AUTOSAR XML (schema 4-0-3)
package /ComponentTypes
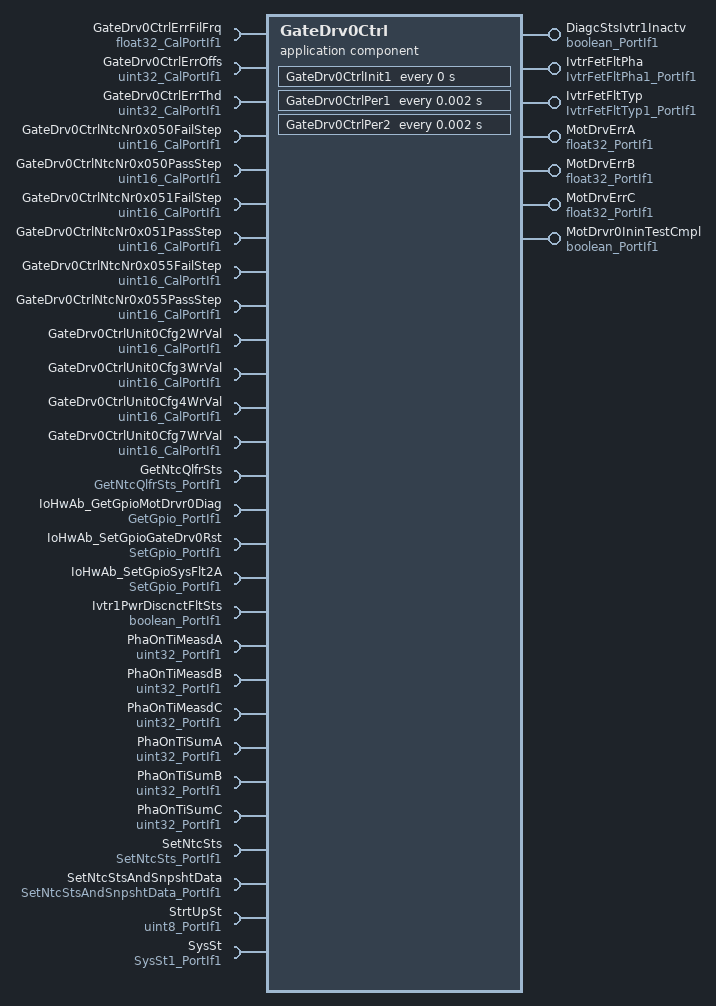
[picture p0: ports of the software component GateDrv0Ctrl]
  application sw component type GateDrv0Ctrl
    7 x provide port:
      DiagcStsIvtr1Inactv: nonqueued-sender-com-spec{data-element=Logl, init-value=0}, provided-interface=boolean_PortIf1
      IvtrFetFltPha: nonqueued-sender-com-spec{data-element=Val, init-value=0}, provided-interface=IvtrFetFltPha1_PortIf1
      IvtrFetFltTyp: nonqueued-sender-com-spec{data-element=Val, init-value=0}, provided-interface=IvtrFetFltTyp1_PortIf1
      MotDrvErrA: nonqueued-sender-com-spec{data-element=Val, init-value=0}, provided-interface=float32_PortIf1
      MotDrvErrB: nonqueued-sender-com-spec{data-element=Val, init-value=0}, provided-interface=float32_PortIf1
      MotDrvErrC: nonqueued-sender-com-spec{data-element=Val, init-value=0}, provided-interface=float32_PortIf1
      MotDrvr0IninTestCmpl: nonqueued-sender-com-spec{data-element=Logl, init-value=0}, provided-interface=boolean_PortIf1
    28 x require port:
      GateDrv0CtrlErrFilFrq: parameter-require-com-spec{init-value=1.8, parameter=Val}, required-interface=float32_CalPortIf1
      GateDrv0CtrlErrOffs: parameter-require-com-spec{init-value=0, parameter=Val}, required-interface=uint32_CalPortIf1
      GateDrv0CtrlErrThd: parameter-require-com-spec{init-value=180000, parameter=Val}, required-interface=uint32_CalPortIf1
      GateDrv0CtrlNtcNr0x050FailStep: parameter-require-com-spec{init-value=4096, parameter=Val}, required-interface=uint16_CalPortIf1
      GateDrv0CtrlNtcNr0x050PassStep: parameter-require-com-spec{init-value=2048, parameter=Val}, required-interface=uint16_CalPortIf1
      GateDrv0CtrlNtcNr0x051FailStep: parameter-require-com-spec{init-value=4096, parameter=Val}, required-interface=uint16_CalPortIf1
      GateDrv0CtrlNtcNr0x051PassStep: parameter-require-com-spec{init-value=2048, parameter=Val}, required-interface=uint16_CalPortIf1
      GateDrv0CtrlNtcNr0x055FailStep: parameter-require-com-spec{init-value=4096, parameter=Val}, required-interface=uint16_CalPortIf1
      GateDrv0CtrlNtcNr0x055PassStep: parameter-require-com-spec{init-value=2048, parameter=Val}, required-interface=uint16_CalPortIf1
      GateDrv0CtrlUnit0Cfg2WrVal: parameter-require-com-spec{init-value=2832, parameter=Val}, required-interface=uint16_CalPortIf1
      GateDrv0CtrlUnit0Cfg3WrVal: parameter-require-com-spec{init-value=3598, parameter=Val}, required-interface=uint16_CalPortIf1
      GateDrv0CtrlUnit0Cfg4WrVal: parameter-require-com-spec{init-value=4622, parameter=Val}, required-interface=uint16_CalPortIf1
      GateDrv0CtrlUnit0Cfg7WrVal: parameter-require-com-spec{init-value=7924, parameter=Val}, required-interface=uint16_CalPortIf1
      GetNtcQlfrSts: client-com-spec=Oper, required-interface=GetNtcQlfrSts_PortIf1
      IoHwAb_GetGpioMotDrvr0Diag: client-com-spec=Oper, required-interface=GetGpio_PortIf1
      IoHwAb_SetGpioGateDrv0Rst: client-com-spec=Oper, required-interface=SetGpio_PortIf1
      IoHwAb_SetGpioSysFlt2A: client-com-spec=Oper, required-interface=SetGpio_PortIf1
      Ivtr1PwrDiscnctFltSts: nonqueued-receiver-com-spec{data-element=Logl, filter=data-filter-type=ALWAYS, init-value=0}, required-interface=boolean_PortIf1
      PhaOnTiMeasdA: nonqueued-receiver-com-spec{data-element=Val, filter=data-filter-type=ALWAYS, init-value=0}, required-interface=uint32_PortIf1
      PhaOnTiMeasdB: nonqueued-receiver-com-spec{data-element=Val, filter=data-filter-type=ALWAYS, init-value=0}, required-interface=uint32_PortIf1
      PhaOnTiMeasdC: nonqueued-receiver-com-spec{data-element=Val, filter=data-filter-type=ALWAYS, init-value=0}, required-interface=uint32_PortIf1
      PhaOnTiSumA: nonqueued-receiver-com-spec{data-element=Val, filter=data-filter-type=ALWAYS, init-value=0}, required-interface=uint32_PortIf1
      PhaOnTiSumB: nonqueued-receiver-com-spec{data-element=Val, filter=data-filter-type=ALWAYS, init-value=0}, required-interface=uint32_PortIf1
      PhaOnTiSumC: nonqueued-receiver-com-spec{data-element=Val, filter=data-filter-type=ALWAYS, init-value=0}, required-interface=uint32_PortIf1
      SetNtcSts: client-com-spec=Oper, required-interface=SetNtcSts_PortIf1
      SetNtcStsAndSnpshtData: client-com-spec=Oper, required-interface=SetNtcStsAndSnpshtData_PortIf1
      StrtUpSt: nonqueued-receiver-com-spec{data-element=Val, filter=data-filter-type=ALWAYS, init-value=0}, required-interface=uint8_PortIf1
      SysSt: nonqueued-receiver-com-spec{data-element=Val, filter=data-filter-type=ALWAYS, init-value=3}, required-interface=SysSt1_PortIf1
    behavior GateDrv0Ctrl_InternalBehavior
      ar-typed-per-instance-memorys:
        36 x data, all with sw-calibration-access=READ-ONLY:
          dGateDrv0CtrlGateDrv0Diag{0..2}Val: type=uint16
          dGateDrv0CtrlGateDrv0OffsStVrfyPrmBitIdx: type=uint8
          dGateDrv0CtrlGateDrv0PhaOnTiSumAExp: type=uint32
          dGateDrv0CtrlGateDrv0PhaOnTiSumBExp: type=uint32
          dGateDrv0CtrlGateDrv0PhaOnTiSumCExp: type=uint32
          dGateDrv0CtrlGateDrv0StsVal: type=uint16
          dGateDrv0CtrlGateDrv0VrfyRes0Val: type=uint16
          dGateDrv0CtrlGateDrv0VrfyRes1Val: type=uint16
          GateDrv0CfgCnt: type=uint8
          GateDrv0CfgSecAtmpt: type=boolean
          GateDrv0Diag{0..2}Val: type=uint16
          GateDrv0OffStChkIdx: type=uint8
          GateDrv0OffStChkSecAtmpt: type=boolean
          GateDrv0OffStCnt: type=uint8
          GateDrv0PhaAFilLp: type=FilLpRec1
          GateDrv0PhaBFilLp: type=FilLpRec1
          GateDrv0PhaCFilLp: type=FilLpRec1
          GateDrv0PhaOnTiSumAPrev: type=uint32
          GateDrv0PhaOnTiSumBPrev: type=uint32
          GateDrv0PhaOnTiSumCPrev: type=uint32
          GateDrv0SpiErrSecAtmpt: type=boolean
          GateDrv0SpiTrsmErrCntr: type=uint32
          GateDrv0St: type=uint8
          GateDrv0StsVal: type=uint16
          GateDrv0VrfyRes0Val: type=uint16
          GateDrv0VrfyRes1Val: type=uint16
          Ivtr0BootstrpSplyFltPrmVal: type=uint8
          Ivtr0GenericFltPrmVal: type=uint8
          Ivtr0InactvSts: type=boolean
          Ivtr0OffStChkCmpl: type=boolean
          IvtrFetFltPhaDataStore: type=IvtrFetFltPha1
          IvtrFetFltTypDataStore: type=IvtrFetFltTyp1
      timing event GateDrvCtrl_InitEvent: start-on-event=GateDrv0CtrlInit1, period=0
      timing event TMT_GateDrvCtrlPer1: start-on-event=GateDrv0CtrlPer1, period=0.002
      timing event TMT_GateDrv0CtrlPer2: start-on-event=GateDrv0CtrlPer2, period=0.002
      explicit-inter-runnable-variables:
        data GateDrv0Ena: type=boolean, init-value=0
        data GateDrv0PhaReasbnDiagcEna: type=boolean, init-value=0
        data Ivtr0PhyFltInpActv: type=boolean, init-value=0
      runnable GateDrv0CtrlInit1
      runnable GateDrv0CtrlPer1
        data-receive-point-by-arguments:
          access REC_StrtUpSt_Val: accessed-variable=StrtUpSt.Val
          access REC_SysSt_Val: accessed-variable=SysSt.Val
        sync call SC_IoHwAb_GetGpioMotDrvr0Diag_Oper: operation=IoHwAb_GetGpioMotDrvr0Diag.Oper, timeout=0
        sync call SC_IoHwAb_SetGpioGateDrv0Rst_Oper: operation=IoHwAb_SetGpioGateDrv0Rst.Oper, timeout=0
        written-local-variables:
          access WRITE_GateDrv0Ena: accessed-variable=GateDrv0Ena
          access WRITE_GateDrv0PhaReasbnDiagcEna: accessed-variable=GateDrv0PhaReasbnDiagcEna
          access WRITE_Ivtr0PhyFltInpActv: accessed-variable=Ivtr0PhyFltInpActv
      runnable GateDrv0CtrlPer2
        data-receive-point-by-arguments:
          7 x access:
            REC_DiagcStsIvtr1Inactv_Logl: accessed-variable=Ivtr1PwrDiscnctFltSts.Logl
            REC_PhaOnTiMeasdA_Val: accessed-variable=PhaOnTiMeasdA.Val
            REC_PhaOnTiMeasdB_Val: accessed-variable=PhaOnTiMeasdB.Val
            REC_PhaOnTiMeasdC_Val: accessed-variable=PhaOnTiMeasdC.Val
            REC_PhaOnTiSumA_Val: accessed-variable=PhaOnTiSumA.Val
            REC_PhaOnTiSumB_Val: accessed-variable=PhaOnTiSumB.Val
            REC_PhaOnTiSumC_Val: accessed-variable=PhaOnTiSumC.Val
        data-send-points:
          7 x access:
            SEND_DiagcStsIvtr1Inactv_Logl: accessed-variable=DiagcStsIvtr1Inactv.Logl
            SEND_IvtrFetFltPha_Val: accessed-variable=IvtrFetFltPha.Val
            SEND_IvtrFetFltTyp_Val: accessed-variable=IvtrFetFltTyp.Val
            SEND_MotDrvErrA_Val: accessed-variable=MotDrvErrA.Val
            SEND_MotDrvErrB_Val: accessed-variable=MotDrvErrB.Val
            SEND_MotDrvErrC_Val: accessed-variable=MotDrvErrC.Val
            SEND_MotDrvr0IninTestCmpl_Logl: accessed-variable=MotDrvr0IninTestCmpl.Logl
        read-local-variables:
          access READ_GateDrv0Ena: accessed-variable=GateDrv0Ena
          access READ_GateDrv0PhaReasbnDiagcEna: accessed-variable=GateDrv0PhaReasbnDiagcEna
          access READ_Ivtr0PhyFltInpActv: accessed-variable=Ivtr0PhyFltInpActv
        6 x sync call, all with timeout=0:
          SC_GetNtcQlfrSts_Oper: operation=GetNtcQlfrSts.Oper
          SC_IoHwAb_GetGpioMotDrvr0Diag_Oper: operation=IoHwAb_GetGpioMotDrvr0Diag.Oper
          SC_IoHwAb_SetGpioGateDrv0Rst_Oper: operation=IoHwAb_SetGpioGateDrv0Rst.Oper
          SC_IoHwAb_SetGpioSysFlt2A_Oper: operation=IoHwAb_SetGpioSysFlt2A.Oper
          SC_SetNtcSts_Oper: operation=SetNtcSts.Oper
          SC_SetNtcStsAndSnpshtData_Oper: operation=SetNtcStsAndSnpshtData.Oper
  swc implementation GateDrv0Ctrl_Implementation: behavior=GateDrv0Ctrl_InternalBehavior
    code-descriptors:
      code Default: artifact-descriptors=autosar-engineering-object={short-label=Default, category=SWSRC}
